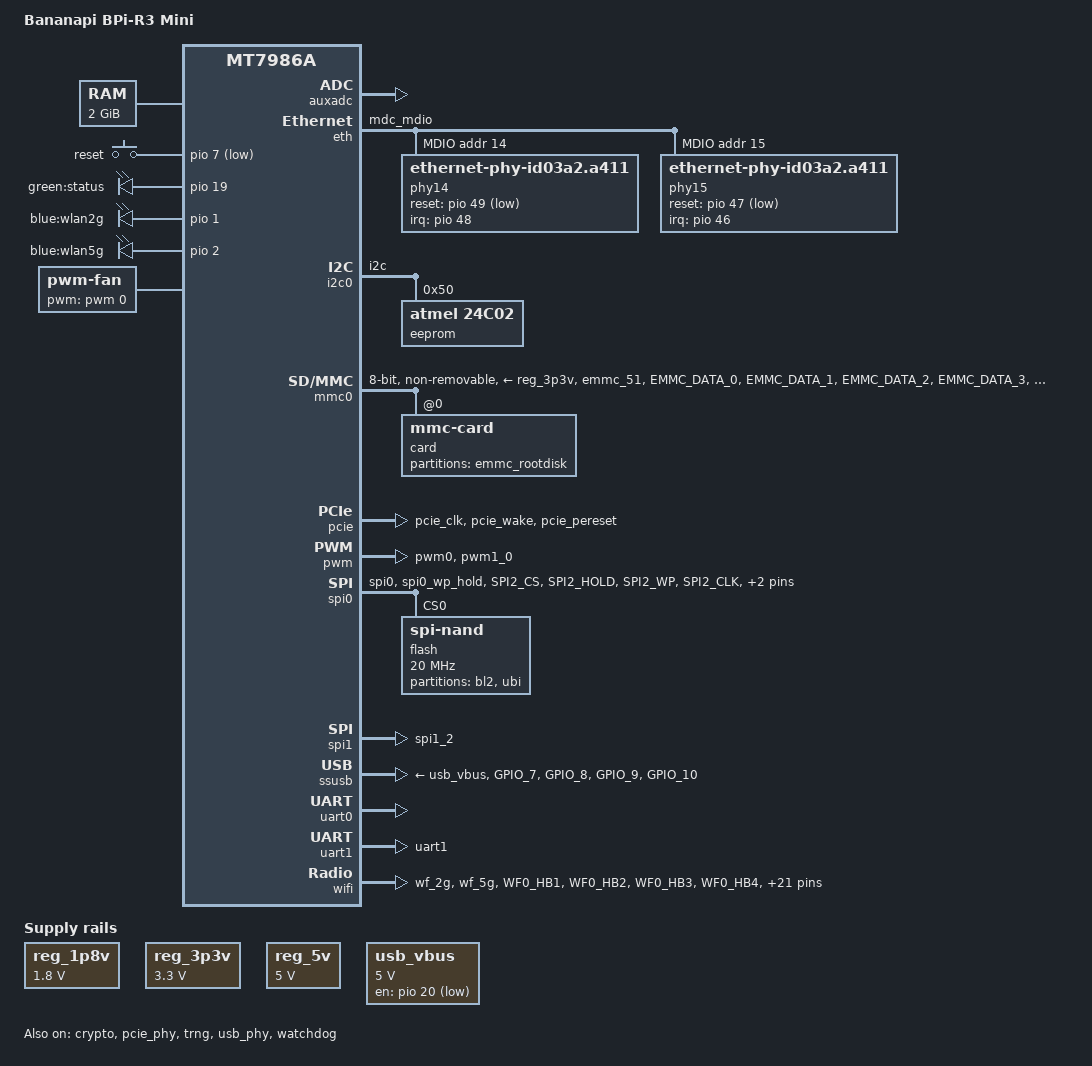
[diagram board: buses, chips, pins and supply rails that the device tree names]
// SPDX-License-Identifier: GPL-2.0-or-later OR MIT
/*
 * Copyright (C) 2023 Tianling Shen <cnsztl@immortalwrt.org>
 */

/dts-v1/;
#include <dt-bindings/gpio/gpio.h>
#include <dt-bindings/input/input.h>
#include <dt-bindings/leds/common.h>

#include "mt7986a.dtsi"

/ {
	model = "Bananapi BPi-R3 Mini";
	chassis-type = "embedded";
	compatible = "bananapi,bpi-r3-mini", "mediatek,mt7986a";

	aliases {
		ethernet0 = &gmac0;
		ethernet1 = &gmac1;
		serial0 = &uart0;

		led-boot = &status_led;
		led-failsafe = &status_led;
		led-running = &status_led;
		led-upgrade = &status_led;
	};

	chosen {
		stdout-path = "serial0:115200n8";
		rootdisk-emmc = <&emmc_rootdisk>;
		rootdisk-spim-nand = <&nand_rootdisk>;
	};

	memory {
		reg = <0 0x40000000 0 0x80000000>;
	};

	gpio-keys {
		compatible = "gpio-keys";

		button-reset {
			label = "reset";
			linux,code = <KEY_RESTART>;
			gpios = <&pio 7 GPIO_ACTIVE_LOW>;
		};
	};

	gpio-leds {
		compatible = "gpio-leds";

		status_led: led-0 {
			label = "green:status";
			gpios = <&pio 19 GPIO_ACTIVE_HIGH>;
		};

		led-1 {
			label = "blue:wlan2g";
			gpios = <&pio 1 GPIO_ACTIVE_HIGH>;
		};

		led-2 {
			label = "blue:wlan5g";
			gpios = <&pio 2 GPIO_ACTIVE_HIGH>;
		};
	};

	fan: pwm-fan {
		compatible = "pwm-fan";
		#cooling-cells = <2>;
		cooling-levels = <255 128 80 0>;
		pwms = <&pwm 0 10000 0>;
		status = "okay";
	};

	reg_1p8v: regulator-1p8v {
		compatible = "regulator-fixed";
		regulator-name = "fixed-1.8V";
		regulator-min-microvolt = <1800000>;
		regulator-max-microvolt = <1800000>;
		regulator-boot-on;
		regulator-always-on;
	};

	reg_3p3v: regulator-3p3v {
		compatible = "regulator-fixed";
		regulator-name = "fixed-3.3V";
		regulator-min-microvolt = <3300000>;
		regulator-max-microvolt = <3300000>;
		regulator-boot-on;
		regulator-always-on;
	};

	reg_5v: regulator-5v {
		compatible = "regulator-fixed";
		regulator-name = "fixed-5V";
		regulator-min-microvolt = <5000000>;
		regulator-max-microvolt = <5000000>;
		regulator-boot-on;
		regulator-always-on;
	};

	usb_vbus: regulator-usb-vbus {
		compatible = "regulator-fixed";
		regulator-name = "usb_vbus";
		regulator-min-microvolt = <5000000>;
		regulator-max-microvolt = <5000000>;
		gpios = <&pio 20 GPIO_ACTIVE_LOW>;
		regulator-boot-on;
	};
};

&auxadc {
	status = "okay";
};

&cpu_thermal {
	cooling-maps {
		cpu-active-low {
			cooling-device = <&fan 1 1>;
			trip = <&cpu_trip_active_low>;
		};

		cpu-active-med {
			cooling-device = <&fan 2 2>;
			trip = <&cpu_trip_active_med>;
		};

		cpu-active-high {
			cooling-device = <&fan 3 3>;
			trip = <&cpu_trip_active_high>;
		};
	};
};

&crypto {
	status = "okay";
};

&eth {
	status = "okay";
	pinctrl-names = "default";
	pinctrl-0 = <&eth_pins>;

	gmac0: mac@0 {
		compatible = "mediatek,eth-mac";
		reg = <0>;
		phy-handle = <&phy14>;
		phy-mode = "2500base-x";
	};

	gmac1: mac@1 {
		compatible = "mediatek,eth-mac";
		reg = <1>;
		phy-handle = <&phy15>;
		phy-mode = "2500base-x";
	};

	mdio: mdio-bus {
		#address-cells = <1>;
		#size-cells = <0>;

		phy14: phy@e {
			compatible = "ethernet-phy-id03a2.a411";
			reg = <14>;
			pinctrl-names = "default";
			pinctrl-0 = <&en8811_pwr_a>;

			airoha,pnswap-rx;

			interrupt-parent = <&pio>;
			interrupts = <48 IRQ_TYPE_EDGE_FALLING>;
			reset-gpios = <&pio 49 GPIO_ACTIVE_LOW>;
			reset-assert-us = <10000>;
			reset-deassert-us = <20000>;

			phy-mode = "2500base-x";
			full-duplex;
			pause;

			leds {
				#address-cells = <1>;
				#size-cells = <0>;

				led@0 {
					reg = <0>;
					function = LED_FUNCTION_LAN;
					color = <LED_COLOR_ID_YELLOW>;
				};

				led@1 {
					reg = <1>;
					function = LED_FUNCTION_LAN;
					color = <LED_COLOR_ID_GREEN>;
				};
			};
		};

		phy15: phy@f {
			compatible = "ethernet-phy-id03a2.a411";
			reg = <15>;
			pinctrl-names = "default";
			pinctrl-0 = <&en8811_pwr_b>;

			airoha,pnswap-rx;

			interrupt-parent = <&pio>;
			interrupts = <46 IRQ_TYPE_EDGE_FALLING>;
			reset-gpios = <&pio 47 GPIO_ACTIVE_LOW>;
			reset-assert-us = <10000>;
			reset-deassert-us = <20000>;

			phy-mode = "2500base-x";
			full-duplex;
			pause;

			leds {
				#address-cells = <1>;
				#size-cells = <0>;

				led@0 {
					reg = <0>;
					function = LED_FUNCTION_WAN;
					color = <LED_COLOR_ID_YELLOW>;
				};

				led@1 {
					reg = <1>;
					function = LED_FUNCTION_WAN;
					color = <LED_COLOR_ID_GREEN>;
				};
			};
		};
	};
};

&i2c0 {
	pinctrl-names = "default";
	pinctrl-0 = <&i2c_pins>;
	status = "okay";

	eeprom@50 {
		compatible = "atmel,24c02";
		reg = <0x50>;
		pagesize = <8>;
		size = <256>;
	};
};

&mmc0 {
	pinctrl-names = "default", "state_uhs";
	pinctrl-0 = <&mmc0_pins_default>;
	pinctrl-1 = <&mmc0_pins_uhs>;
	bus-width = <8>;
	max-frequency = <200000000>;
	cap-mmc-highspeed;
	mmc-hs200-1_8v;
	mmc-hs400-1_8v;
	hs400-ds-delay = <0x14014>;
	vmmc-supply = <&reg_3p3v>;
	vqmmc-supply = <&reg_1p8v>;
	non-removable;
	no-sd;
	no-sdio;
	status = "okay";

	card@0 {
		compatible = "mmc-card";
		reg = <0>;

		block {
			compatible = "block-device";
			partitions {
				emmc_rootdisk: block-partition-production {
					partname = "production";
				};
			};
		};
	};
};

&pcie {
	pinctrl-names = "default";
	pinctrl-0 = <&pcie_pins>;
	status = "okay";
};

&pcie_phy {
	status = "okay";
};

&pio {
	en8811_pwr_a: en8811-pwr-a {
		pins = "GPIO_11";
		drive-strength = <8>;
		mediatek,pull-down-adv = <1>;
		output-low;
	};

	en8811_pwr_b: en8811-pwr-b {
		pins = "GPIO_12";
		drive-strength = <8>;
		mediatek,pull-down-adv = <1>;
		output-low;
	};

	eth_pins: eth-pins {
		mux {
			function = "eth";
			groups = "mdc_mdio";
		};
	};

	i2c_pins: i2c-pins {
		mux {
			function = "i2c";
			groups = "i2c";
		};
	};

	mmc0_pins_default: mmc0-pins-default {
		mux {
			function = "emmc";
			groups = "emmc_51";
		};
		conf-cmd-dat {
			pins = "EMMC_DATA_0", "EMMC_DATA_1", "EMMC_DATA_2",
			       "EMMC_DATA_3", "EMMC_DATA_4", "EMMC_DATA_5",
			       "EMMC_DATA_6", "EMMC_DATA_7", "EMMC_CMD";
			input-enable;
			drive-strength = <4>;
			mediatek,pull-up-adv = <1>;
		};
		conf-clk {
			pins = "EMMC_CK";
			drive-strength = <6>;
			mediatek,pull-down-adv = <2>;
		};
		conf-ds {
			pins = "EMMC_DSL";
			mediatek,pull-down-adv = <2>;
		};
		conf-rst {
			pins = "EMMC_RSTB";
			drive-strength = <4>;
			mediatek,pull-up-adv = <1>;
		};
	};

	mmc0_pins_uhs: mmc0-uhs-pins {
		mux {
			function = "emmc";
			groups = "emmc_51";
		};
		conf-cmd-dat {
			pins = "EMMC_DATA_0", "EMMC_DATA_1", "EMMC_DATA_2",
			       "EMMC_DATA_3", "EMMC_DATA_4", "EMMC_DATA_5",
			       "EMMC_DATA_6", "EMMC_DATA_7", "EMMC_CMD";
			input-enable;
			drive-strength = <4>;
			mediatek,pull-up-adv = <1>;
		};
		conf-clk {
			pins = "EMMC_CK";
			drive-strength = <6>;
			mediatek,pull-down-adv = <2>;
		};
		conf-ds {
			pins = "EMMC_DSL";
			mediatek,pull-down-adv = <2>;
		};
		conf-rst {
			pins = "EMMC_RSTB";
			drive-strength = <4>;
			mediatek,pull-up-adv = <1>;
		};
	};

	pcie_pins: pcie-pins {
		mux {
			function = "pcie";
			groups = "pcie_clk", "pcie_wake", "pcie_pereset";
		};
	};

	pwm_pins: pwm-pins {
		mux {
			function = "pwm";
			groups = "pwm0", "pwm1_0";
		};
	};

	spi_flash_pins: spi-flash-pins {
		mux {
			function = "spi";
			groups = "spi0", "spi0_wp_hold";
		};
		conf-pu {
			pins = "SPI2_CS", "SPI2_HOLD", "SPI2_WP";
			drive-strength = <8>;
			mediatek,pull-up-adv = <0>;
		};
		conf-pd {
			pins = "SPI2_CLK", "SPI2_MOSI", "SPI2_MISO";
			drive-strength = <8>;
			mediatek,pull-down-adv = <0>;
		};
	};

	spic_pins: spic-pins {
		mux {
			function = "spi";
			groups = "spi1_2";
		};
	};

	uart1_pins: uart1-pins {
		mux {
			function = "uart";
			groups = "uart1";
		};
	};

	usb_ngff_pins: usb-ngff-pins {
		ngff-pe-rst {
			pins = "GPIO_7";
			drive-strength = <8>;
			mediatek,pull-up-adv = <1>;
		};
		ngff-wwan-off {
			pins = "GPIO_8";
			drive-strength = <8>;
			mediatek,pull-up-adv = <1>;
		};
		ngff-pwr-off {
			pins = "GPIO_9";
			drive-strength = <8>;
			mediatek,pull-up-adv = <1>;
		};
		ngff-rst {
			pins = "GPIO_10";
			drive-strength = <8>;
			mediatek,pull-up-adv = <1>;
		};
	};

	wf_2g_5g_pins: wf-2g-5g-pins {
		mux {
			function = "wifi";
			groups = "wf_2g", "wf_5g";
		};
		conf {
			pins = "WF0_HB1", "WF0_HB2", "WF0_HB3", "WF0_HB4",
			       "WF0_HB0", "WF0_HB0_B", "WF0_HB5", "WF0_HB6",
			       "WF0_HB7", "WF0_HB8", "WF0_HB9", "WF0_HB10",
			       "WF0_TOP_CLK", "WF0_TOP_DATA", "WF1_HB1",
			       "WF1_HB2", "WF1_HB3", "WF1_HB4", "WF1_HB0",
			       "WF1_HB5", "WF1_HB6", "WF1_HB7", "WF1_HB8",
			       "WF1_TOP_CLK", "WF1_TOP_DATA";
			drive-strength = <4>;
		};
	};

	wf_dbdc_pins: wf-dbdc-pins {
		mux {
			function = "wifi";
			groups = "wf_dbdc";
		};
		conf {
			pins = "WF0_HB1", "WF0_HB2", "WF0_HB3", "WF0_HB4",
			       "WF0_HB0", "WF0_HB0_B", "WF0_HB5", "WF0_HB6",
			       "WF0_HB7", "WF0_HB8", "WF0_HB9", "WF0_HB10",
			       "WF0_TOP_CLK", "WF0_TOP_DATA", "WF1_HB1",
			       "WF1_HB2", "WF1_HB3", "WF1_HB4", "WF1_HB0",
			       "WF1_HB5", "WF1_HB6", "WF1_HB7", "WF1_HB8",
			       "WF1_TOP_CLK", "WF1_TOP_DATA";
			drive-strength = <4>;
		};
	};
};

&pwm {
	pinctrl-names = "default";
	pinctrl-0 = <&pwm_pins>;
	status = "okay";
};

&spi0 {
	pinctrl-names = "default";
	pinctrl-0 = <&spi_flash_pins>;
	status = "okay";

	flash@0 {
		compatible = "spi-nand";
		#address-cells = <1>;
		#size-cells = <1>;
		reg = <0>;

		spi-max-frequency = <20000000>;
		spi-tx-bus-width = <4>;
		spi-rx-bus-width = <4>;

		partitions {
			compatible = "fixed-partitions";
			#address-cells = <1>;
			#size-cells = <1>;

			partition@0 {
				label = "bl2";
				reg = <0x00000 0x100000>;
				read-only;
			};

			partition@100000 {
				label = "ubi";
				reg = <0x100000 0x7f00000>;
				compatible = "linux,ubi";

				volumes {
					nand_rootdisk: ubi-volume-fit {
						volname = "fit";
					};
				};
			};
		};
	};
};

&spi1 {
	pinctrl-names = "default";
	pinctrl-0 = <&spic_pins>;
	status = "okay";
};

&ssusb {
	pinctrl-names = "default";
	pinctrl-0 = <&usb_ngff_pins>;
	vusb33-supply = <&reg_3p3v>;
	vbus-supply = <&usb_vbus>;
	status = "okay";
};

&trng {
	status = "okay";
};

&uart0 {
	status = "okay";
};

&uart1 {
	pinctrl-names = "default";
	pinctrl-0 = <&uart1_pins>;
	status = "okay";
};

&usb_phy {
	status = "okay";
};

&watchdog {
	status = "okay";
};

&wifi {
	pinctrl-names = "default", "dbdc";
	pinctrl-0 = <&wf_2g_5g_pins>;
	pinctrl-1 = <&wf_dbdc_pins>;
	status = "okay";

	mediatek,eeprom-data = <0x86790200 0x000c4326 0x60000000 0x00000000 0x00000000 0x00000000 0x00000000 0x00000000
				0x00000000 0x00000000 0x00000000 0x00000000 0x00000000 0x00000000 0x00000000 0x00000000
				0x00000000 0x00000000 0x00000000 0x00000000 0x00000000 0x00000000 0x00000000 0x00000000
				0x00000000 0x00000000 0x00000000 0x00000000 0x00000000 0x00000000 0x00000000 0x00000000
				0x00000000 0x00000000 0x00000000 0x00000000 0x00000000 0x00000000 0x00000000 0x00000000
				0x00000000 0x00000000 0x00000000 0x00000000 0x00000000 0x00000000 0x00000000 0x00000000
				0x00000000 0x00000000 0x00000000 0x00000000 0x00000000 0x00000000 0x00000000 0x00000000
				0x00000000 0x00000000 0x00000000 0x00000000 0x00000000 0x00000000 0x00000000 0x00000000
				0x00000000 0x00000000 0x00000000 0x00000000 0x00000000 0x00000000 0x00000000 0x00000000
				0x00000000 0x00000000 0x00000000 0x00000000 0x00000000 0x00000000 0x00000000 0x00000000
				0x00000000 0x00000000 0x00000000 0x00000000 0x00000000 0x00000000 0x00000000 0x00000000
				0x00000000 0x00000000 0x00000000 0x00000000 0x00000000 0x00000000 0x00000000 0x00000000
				0x00000000 0x00000000 0x00000000 0x00000000 0x125b486c 0x00280000 0x05d00000 0x00000000
				0x00000000 0x00000000 0x00000000 0x00000000 0x00000000 0x00000000 0x00000000 0x00000000
				0x00000000 0x00000000 0x00000000 0x00000000 0x00000000 0x00000000 0x00000000 0x00000000
				0x00000000 0x00000000 0x00000000 0x00000000 0x00000000 0x00000000 0x00000000 0x00000000
				0x00000000 0x00000000 0x00000000 0x00000000 0x00000000 0x00000000 0x00000000 0x00000000
				0x00000000 0x00000000 0x00000000 0x00000000 0x00000000 0x00000000 0x00000000 0x00000000
				0x00000000 0x00000000 0x00000000 0x00000000 0x00000000 0x00000000 0x00000000 0x00000000
				0x00000000 0x00000000 0x00000000 0x00000000 0x0c000000 0x00000000 0x00000000 0x00000000
				0x00000000 0x00000000 0x00000000 0x00000000 0x00000000 0x00000000 0x00000000 0x00000000
				0x00000000 0x00000000 0x00000000 0x00000000 0x00000000 0x00000000 0x00000000 0x00000000
				0x00000000 0x00000000 0x00000000 0x00000000 0x00000000 0x00000000 0x00000000 0x00000000
				0x00000000 0x00000000 0x00000000 0x00000000 0x00000000 0x00000000 0x00000000 0x00000000
				0x00000000 0x00000000 0x00000000 0x00000000 0x00000000 0x00000000 0x00000000 0x00000000
				0x00000000 0x00000000 0x00000000 0x00000000 0x00000000 0x00000000 0x00000000 0x00000000
				0x00000000 0x00000000 0x00000000 0x00000000 0x00000000 0x00000000 0x00000000 0x00000000
				0x00000000 0x00000000 0x00000000 0x00000000 0x00000000 0x00000000 0x00000000 0x00000000
				0x00000000 0x00000000 0x00000000 0x00000000 0x00000000 0x00000000 0x00000000 0x00000000
				0x00000000 0x00000000 0x00000000 0x00000000 0x00000000 0x00000000 0x00000000 0x00000000
				0x00000000 0x00000000 0x00000000 0x00000000 0x00000000 0x00000000 0x00000000 0x00000000
				0x00000000 0x00000012 0x12120000 0x00000000 0x00000000 0x00002222 0x22223333 0x33333333
				0x33333333 0x33333333 0x33333333 0x33333333 0x33333333 0x33330000 0x00000000 0x00000000
				0x00000000 0x00000000 0x00000000 0x00000000 0x00000000 0x00000000 0x00000000 0x00000000
				0x00292929 0x29282828 0x28282828 0x28282828 0x28282828 0x28282828 0x28000000 0x00000000
				0x00000000 0x00242424 0x24222222 0x22242424 0x24222222 0x22242424 0x24222222 0x22242424
				0x24222222 0x22000000 0x00000000 0x00000000 0x00000000 0x00000000 0x00000000 0x00000000
				0x00000000 0x00000000 0x00000000 0x00000000 0x00000000 0x00000000 0x00000000 0x00000000
				0x00000000 0x00000000 0x00000000 0x00000000 0x00000000 0x00000000 0x00000000 0x00000000
				0x00000000 0x00000000 0x00000000 0x00000000 0x00000000 0x00000000 0x00000000 0x00000000
				0x00000000 0x00000000 0x00000000 0x00000000 0x00000000 0x00000000 0x00000000 0x00000000
				0x00000000 0x00000000 0x00000000 0x00000000 0x00000000 0x00000000 0x00000000 0x00000000
				0x00000000 0x00000000 0x00000000 0x00000000 0x00000000 0x00000000 0x00000000 0x00000000
				0x00000000 0x00000000 0x00000000 0x00000000 0x00000000 0x00000000 0x00000000 0x00000000
				0x00000000 0x007f7f7f 0xd1d1dddd 0xe9e9f5f5 0x01010909 0x1515d1d1 0xdddde9e9 0xf5f5fdfd
				0x09091515 0xd1d1dddd 0xe9e9f5f5 0xfdfd0909 0x1515d1d1 0xdddde9e9 0xf5f5fdfd 0x09091515
				0x00000000 0x00000000 0x00000000 0x00000000 0x00000000 0x00000000 0x00000000 0x00000000
				0x00000000 0x00000000 0x00000000 0x00000000 0x00000000 0x00000000 0x00000000 0x00000000
				0x0efefc00 0x00000000 0x00000000 0x00000000 0x00000000 0x00000000 0x00000000 0x00000000
				0x00000000 0x00000000 0x00000000 0x00000000 0x00000000 0x00000000 0x00000000 0x00000000
				0x00000000 0x00000000 0x00000000 0x00000000 0x00000000 0x00000000 0x00000000 0x00000000
				0x00000000 0x00000000 0x00000000 0x00000000 0x00000000 0x00000000 0x00000000 0x00000000
				0x00000000 0x00000000 0x00000000 0x00000000 0x00000000 0x00000000 0x00000000 0x00000000
				0x00000000 0x00000000 0x00000000 0x00000000 0x00000000 0x00000000 0x00000000 0x00000000
				0x00000000 0x00000000 0x00000000 0x00000000 0x00000000 0x00000000 0x00000000 0x00000000
				0x00000000 0x00000000 0x00000000 0x00000000 0x00000000 0x00000000 0x00000000 0x00000000
				0x00000000 0x00000000 0x00000000 0x00000000 0x00000000 0x00000000 0x00000000 0x00000000
				0x00000000 0x00000000 0x00000000 0x00000000 0x00000000 0x00000000 0x00000000 0x00000000
				0x00000000 0x00000000 0x00000000 0x00000000 0x00000000 0x00000000 0x00000000 0x00000000
				0x00000000 0x00000000 0x00000000 0x00000000 0x00000000 0x00000000 0x00000000 0x00000000
				0x00000000 0x00000000 0x00000000 0x00000000 0x021e021e 0x02000200 0x02370237 0x02370237
				0x02370237 0x02370237 0x02370237 0x02370237 0x02370237 0x02370237 0x02370237 0x02370237
				0x02370237 0x02370237 0x02370237 0x02370237 0x002200c6 0xc6c4c4c3 0x0000c1c2 0xc1838383
				0x838686c1 0xc1838383 0x838686c2 0xc1c18181 0x82838585 0x8686c1c1 0x81818283 0x85858686
				0xc1c18181 0x82838585 0x8686c1c1 0x81818283 0x85858686 0xc1c18181 0x82838585 0x8686c5c5
				0xc3c100c2 0xc3c2c200 0x81828383 0xc2c2c200 0x81828383 0xc3c1c1c1 0x81828384 0x84c2c2c2
				0xc2008182 0x83838585 0xc2c2c200 0x81828383 0x8585c1c1 0xc1818283 0x84848686 0x82828484
				0x85868787 0x8989c2c2 0xc2008182 0x83838585 0xc2c2c200 0x81828383 0x8585c2c2 0xc2008182
				0x83838585 0xc4c4c2c1 0x00c3c3c3 0xc1008183 0x838686c3 0xc3c3c100 0x81838386 0x86c2c2c2
				0x00818284 0x84868682 0x82828485 0x8688888b 0x8bc3c3c3 0xc1008183 0x838686c3 0xc3c3c100
				0x81838386 0x86c3c3c3 0xc1008183 0x83868600 0x00000000 0x00000000 0x00000000 0x00000000
				0x00000000 0x00000000 0x00000000 0x00000000 0x00000000 0x00000000 0x00000000 0x00000000
				0x00000000 0x00000000 0x00000000 0x00000000 0x00000000 0x00000000 0x00000000 0x00000000
				0x00000000 0x00000000 0x00000000 0x00000000 0x00000000 0x00000000 0x00000000 0x00000000
				0x00000000 0x00000000 0x00000000 0x00000000 0x00000000 0x00000000 0x00000000 0x00000000
				0x00000000 0x00000000 0x00000000 0x00000000 0x00000000 0x00000000 0x00000000 0x00000000
				0x00000000 0x00000000 0x00000000 0x00000000 0x00bd0000 0x00000000 0x00000000 0x00000000
				0x00000000 0x00000000 0x00c50000 0x00000000 0x00000000 0x00000000 0x00000000 0x00000000
				0x00000000 0x00000000 0x00000000 0x00000000 0x00000000 0x00000000 0x00000000 0x00000000
				0x00000000 0x00000000 0x00000000 0x00000000 0x00000000 0x00000000 0x00000000 0x00000000
				0x00000000 0x00000000 0x00000000 0x00000000 0x00000000 0x00000000 0x00000000 0x00000000
				0x00495256 0x55555555 0x004a5251 0x51515151 0x004a5355 0x56565656 0x0049504e 0x51515151
				0x00495150 0x54545454 0x00495051 0x51515151 0x00495251 0x50505050 0x00495251 0x51515151
				0x00495251 0x54545454 0x00495150 0x54545454 0x00495352 0x51515151 0x00495353 0x52525252
				0x00495150 0x50505050 0x00495152 0x54545454 0x00495251 0x53535353 0x00000000 0x00000000
				0x00000000 0x00000000 0x00000000 0x00000000 0x00000000 0x00000000 0x00000000 0x00000000
				0x00000000 0x00000000 0x00000000 0x00000000 0x00000000 0x00000000 0x00000000 0x00000000
				0x00000000 0x00000000 0x00000000 0x00000000 0x00000000 0x00000000 0x00000000 0x00000000
				0x00000000 0x00000000 0x00000000 0x00000000 0xd1d1dddd 0xe9e9f5f5 0xfdfd1414 0x1d1d0000
				0x00000000 0x00000000 0x00000000 0x00000000 0x00000000 0x00000000 0x00000000 0x00000000
				0x00000000 0x00000000 0x00000000 0x00000000 0x00000000 0x00000000 0x00000000 0x00000000
				0x00000000 0x00000000 0x00000000 0x00000000 0x00000000 0x00000000 0x00000000 0x00000000
				0x00000000 0x00000000 0x00000000 0x00000000 0x00000000 0x00000000 0x00000000 0x00000000
				0x00000000 0x00000000 0x00000000 0x00000000 0x00000000 0x00000000 0x00000000 0x00000000
				0x00000000 0x00000000 0x00000000 0x00000000 0x00000000 0x00000000 0x00000000 0x00000000
				0x00000000 0x00000000 0x00000000 0x00000000 0x00000000 0x00000000 0x00000000 0x00000000
				0x00000000 0x00000000 0x00000000 0x00000000 0x00000000 0x00000000 0x00000000 0x00000000
				0x00000000 0x00000000 0x00000000 0x00000000 0x00000000 0x00000000 0x00000000 0x00000000
				0x00000000 0x00000000 0x00000000 0x00000000 0x00000000 0x00000000 0x00000000 0x00000000
				0x00000000 0x00000000 0x00000000 0x00000000 0x00000000 0x00000000 0x00000000 0x00000000
				0x00000000 0x00000000 0x00000000 0x00000000 0x00000000 0x00000000 0x00000000 0x00000000
				0x85840000 0xc3c4c382 0x828281c1 0xc4c5c400 0x0000c1c3 0xc4c4c481 0x8181c1c2 0x00000000
				0x00000000 0x00000000 0x00000000 0x00000000 0x00000000 0x00000000 0x00000000 0x00000000
				0x00000000 0x00000000 0x00000000 0x00000000 0x00000000 0x00000000 0x00000000 0x00000000
				0xc0bbc0bb 0xc0bbc0bb 0x40c5c0c4 0xc0c3c0c3 0x40c340c5 0x40c4c0c3 0x40c3c0c2 0xc0c5c0c4
				0x40c440c4 0xc0c3c0c5 0xc0c440c4 0x40c4c0c3 0x00000000 0x00000000 0x00000000 0x00000000
				0x00000000 0x00000000 0x40c640c6 0x40c640c6 0x40c640c6 0x40c640c6 0x40c640c6 0x40c640c6
				0x40c640c6 0x40c640c6 0x40c640c6 0x40c640c6 0x40c640c6 0x40c640c6 0x40c640c6 0x40c640c6
				0x40c640c6 0x40c640c6 0x00000000 0x00000000 0x00000000 0x00000000 0x00000000 0x00000000
				0x00000000 0x00000000 0x00000000 0x00000000 0x00000000 0x00000000 0x00000000 0x00000000
				0x00000000 0x00000000 0x00000000 0x00000000 0x00000000 0x00000000 0x00000000 0x00000000
				0x00000000 0x00000000 0x00000000 0x00000000 0x00000000 0x00000000 0x00000000 0x00000000
				0x00000000 0x00000000 0x00000000 0x00000000 0x00000000 0x00000000 0x00000000 0x00000000
				0x00000000 0x00000000 0x00000000 0x00000000 0x00000000 0x00000000 0x00000000 0x00000000
				0x00000000 0x00000000 0x00000000 0x00000000 0x00000000 0x00000000 0x00000000 0x00000000
				0x00000000 0x00000000 0x00000000 0x00000000 0x00000000 0x00000000 0x00000000 0x00000000
				0x00000000 0x00000000 0x00000000 0x00000000 0x00000000 0x00000000 0x00000000 0x00000000
				0x00000000 0x00000000 0x00000000 0x00000000 0x00000000 0x00000000 0x00000000 0x00000000
				0x00000000 0x00000000 0x00000000 0x00000000 0x00000000 0x00000000 0x00000000 0x00000000
				0x00000000 0x00000000 0x00000000 0x00000000 0x00000000 0x00000000 0x00000000 0x00000000
				0x00000000 0x00000000 0x00000000 0x00000000 0x00000000 0x00000000 0x00000000 0x00000000
				0x00000000 0x00000000 0x00000000 0x00000000 0x00000000 0x00000000 0x00000000 0x00000000
				0x00000000 0x00000000 0x00000000 0x00000000 0x00000000 0x00000000 0x00000000 0x00000000
				0x00000000 0x00000000 0x00000000 0x00000000 0x00000000 0x00000000 0x00000000 0x00000000
				0x00000000 0x00000000 0x00000000 0x00000000 0x00000000 0x00000000 0x00000000 0x00000000
				0x00000000 0x00000000 0x00000000 0x00000000 0x00000000 0x00000000 0x00000000 0x00000000
				0x00000000 0x00000000 0x00000000 0x00000000 0x00000000 0x00000000 0x00000000 0x00000000
				0x00000000 0x00000000 0x00000000 0x00000000 0x00000000 0x00000000 0x00000000 0x00000000>;
};
